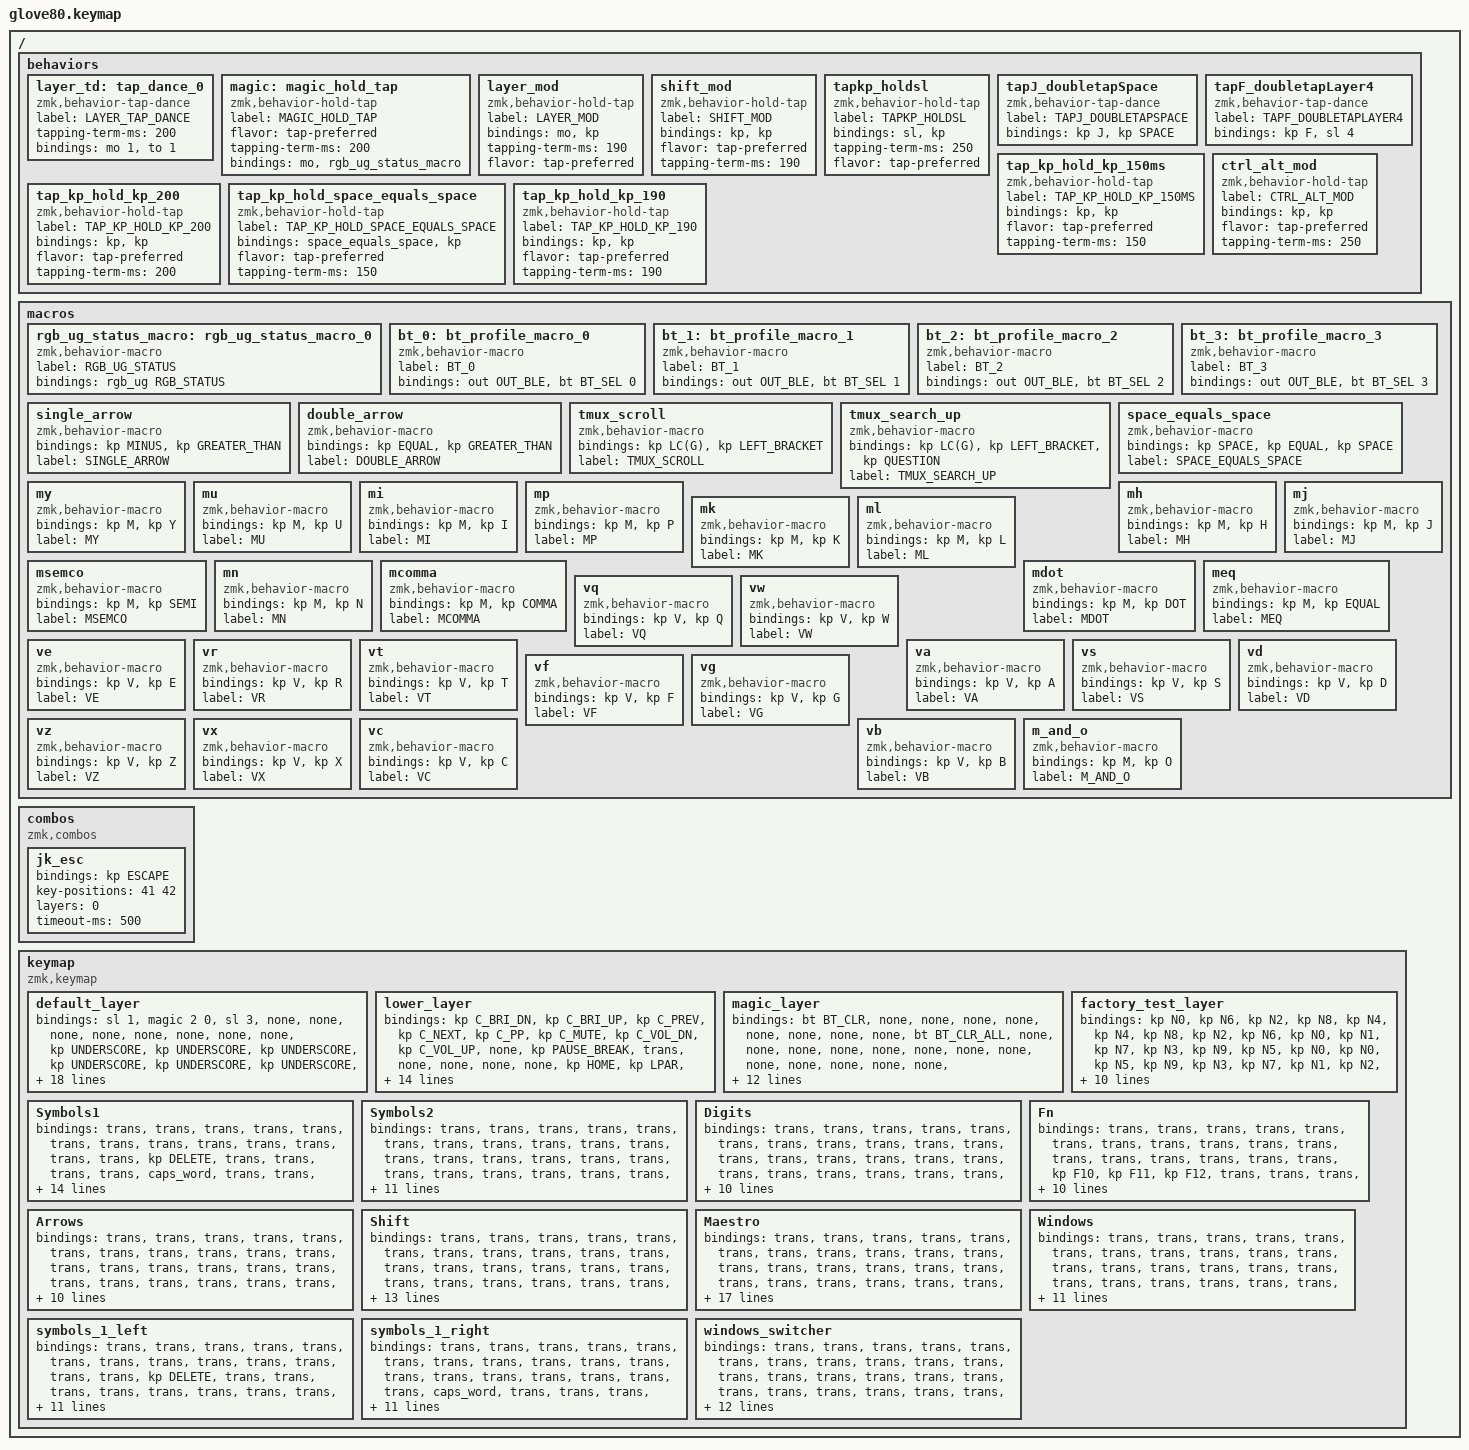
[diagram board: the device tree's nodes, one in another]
/*
 * Copyright (c) 2020 The ZMK Contributors
 *
 * SPDX-License-Identifier: MIT
 */

#include <behaviors.dtsi>
#include <dt-bindings/zmk/bt.h>
#include <dt-bindings/zmk/keys.h>
#include <dt-bindings/zmk/outputs.h>
#include <dt-bindings/zmk/rgb.h>

#define HYPER LC(LS(LG(LALT)))

// layers

#define DEFAULT 0
#define LOWER 1
#define MAGIC 2
#define FACTORY_TEST 3

/ {
    behaviors {
        // For the "layer" key, it'd nice to be able to use it as either a shift or a toggle.
        // Configure it as a tap dance, so the first tap (or hold) is a &mo and the second tap is a &to

        layer_td: tap_dance_0 {
            compatible = "zmk,behavior-tap-dance";
            label = "LAYER_TAP_DANCE";
            #binding-cells = <0>;
            tapping-term-ms = <200>;
            bindings = <&mo 1>, <&to 1>;
        };

        magic: magic_hold_tap {
            compatible = "zmk,behavior-hold-tap";
            label = "MAGIC_HOLD_TAP";
            #binding-cells = <2>;
            flavor = "tap-preferred";
            tapping-term-ms = <200>;
            bindings = <&mo>, <&rgb_ug_status_macro>;
        };

        layer_mod: layer_mod {
            compatible = "zmk,behavior-hold-tap";
            label = "LAYER_MOD";
            bindings = <&mo>, <&kp>;

            #binding-cells = <2>;
            tapping-term-ms = <190>;
            flavor = "tap-preferred";
        };

        shift_mod: shift_mod {
            compatible = "zmk,behavior-hold-tap";
            label = "SHIFT_MOD";
            bindings = <&kp>, <&kp>;

            #binding-cells = <2>;
            flavor = "tap-preferred";
            tapping-term-ms = <190>;
        };

        tapkp_holdsl: tapkp_holdsl {
            compatible = "zmk,behavior-hold-tap";
            label = "TAPKP_HOLDSL";
            bindings = <&sl>, <&kp>;

            #binding-cells = <2>;
            tapping-term-ms = <250>;
            flavor = "tap-preferred";
        };

        tapJ_doubletapSpace: tapJ_doubletapSpace {
            compatible = "zmk,behavior-tap-dance";
            label = "TAPJ_DOUBLETAPSPACE";
            #binding-cells = <0>;
            bindings = <&kp J>, <&kp SPACE>;
        };

        tapF_doubletapLayer4: tapF_doubletapLayer4 {
            compatible = "zmk,behavior-tap-dance";
            label = "TAPF_DOUBLETAPLAYER4";
            #binding-cells = <0>;
            bindings = <&kp F>, <&sl 4>;
        };

        tap_kp_hold_kp_150ms: tap_kp_hold_kp_150ms {
            compatible = "zmk,behavior-hold-tap";
            label = "TAP_KP_HOLD_KP_150MS";
            bindings = <&kp>, <&kp>;

            #binding-cells = <2>;
            flavor = "tap-preferred";
            tapping-term-ms = <150>;
        };

        ctrl_alt_mod: ctrl_alt_mod {
            compatible = "zmk,behavior-hold-tap";
            label = "CTRL_ALT_MOD";
            bindings = <&kp>, <&kp>;

            #binding-cells = <2>;
            flavor = "tap-preferred";
            tapping-term-ms = <250>;
        };

        tap_kp_hold_kp_200: tap_kp_hold_kp_200 {
            compatible = "zmk,behavior-hold-tap";
            label = "TAP_KP_HOLD_KP_200";
            bindings = <&kp>, <&kp>;

            #binding-cells = <2>;
            flavor = "tap-preferred";
            tapping-term-ms = <200>;
        };

        tap_kp_hold_space_equals_space: tap_kp_hold_space_equals_space {
            compatible = "zmk,behavior-hold-tap";
            label = "TAP_KP_HOLD_SPACE_EQUALS_SPACE";
            bindings = <&space_equals_space>, <&kp>;

            #binding-cells = <2>;
            flavor = "tap-preferred";
            tapping-term-ms = <150>;
        };

        tap_kp_hold_kp_190: tap_kp_hold_kp_190 {
            compatible = "zmk,behavior-hold-tap";
            label = "TAP_KP_HOLD_KP_190";
            bindings = <&kp>, <&kp>;

            #binding-cells = <2>;
            flavor = "tap-preferred";
            tapping-term-ms = <190>;
        };
    };

    macros {
        rgb_ug_status_macro: rgb_ug_status_macro_0 {
            label = "RGB_UG_STATUS";
            compatible = "zmk,behavior-macro";
            #binding-cells = <0>;
            bindings = <&rgb_ug RGB_STATUS>;
        };

        bt_0: bt_profile_macro_0 {
            label = "BT_0";
            compatible = "zmk,behavior-macro";
            #binding-cells = <0>;
            bindings = <&out OUT_BLE &bt BT_SEL 0>;
        };

        bt_1: bt_profile_macro_1 {
            label = "BT_1";
            compatible = "zmk,behavior-macro";
            #binding-cells = <0>;
            bindings = <&out OUT_BLE &bt BT_SEL 1>;
        };

        bt_2: bt_profile_macro_2 {
            label = "BT_2";
            compatible = "zmk,behavior-macro";
            #binding-cells = <0>;
            bindings = <&out OUT_BLE &bt BT_SEL 2>;
        };

        bt_3: bt_profile_macro_3 {
            label = "BT_3";
            compatible = "zmk,behavior-macro";
            #binding-cells = <0>;
            bindings = <&out OUT_BLE &bt BT_SEL 3>;
        };

        single_arrow: single_arrow {
            compatible = "zmk,behavior-macro";
            #binding-cells = <0>;
            bindings = <&kp MINUS &kp GREATER_THAN>;
            label = "SINGLE_ARROW";
        };

        double_arrow: double_arrow {
            compatible = "zmk,behavior-macro";
            #binding-cells = <0>;
            bindings = <&kp EQUAL &kp GREATER_THAN>;
            label = "DOUBLE_ARROW";
        };

        tmux_scroll: tmux_scroll {
            compatible = "zmk,behavior-macro";
            #binding-cells = <0>;
            bindings = <&kp LC(G) &kp LEFT_BRACKET>;
            label = "TMUX_SCROLL";
        };

        tmux_search_up: tmux_search_up {
            compatible = "zmk,behavior-macro";
            #binding-cells = <0>;
            bindings = <&kp LC(G) &kp LEFT_BRACKET &kp QUESTION>;
            label = "TMUX_SEARCH_UP";
        };

        space_equals_space: space_equals_space {
            compatible = "zmk,behavior-macro";
            #binding-cells = <0>;
            bindings = <&kp SPACE &kp EQUAL &kp SPACE>;
            label = "SPACE_EQUALS_SPACE";
        };

        my: my {
            compatible = "zmk,behavior-macro";
            #binding-cells = <0>;
            bindings = <&kp M &kp Y>;
            label = "MY";
        };

        mu: mu {
            compatible = "zmk,behavior-macro";
            #binding-cells = <0>;
            bindings = <&kp M &kp U>;
            label = "MU";
        };

        mi: mi {
            compatible = "zmk,behavior-macro";
            #binding-cells = <0>;
            bindings = <&kp M &kp I>;
            label = "MI";
        };

        mp: mp {
            compatible = "zmk,behavior-macro";
            #binding-cells = <0>;
            bindings = <&kp M &kp P>;
            label = "MP";
        };

        mh: mh {
            compatible = "zmk,behavior-macro";
            #binding-cells = <0>;
            bindings = <&kp M &kp H>;
            label = "MH";
        };

        mj: mj {
            compatible = "zmk,behavior-macro";
            #binding-cells = <0>;
            bindings = <&kp M &kp J>;
            label = "MJ";
        };

        mk: mk {
            compatible = "zmk,behavior-macro";
            #binding-cells = <0>;
            bindings = <&kp M &kp K>;
            label = "MK";
        };

        ml: ml {
            compatible = "zmk,behavior-macro";
            #binding-cells = <0>;
            bindings = <&kp M &kp L>;
            label = "ML";
        };

        msemco: msemco {
            compatible = "zmk,behavior-macro";
            #binding-cells = <0>;
            bindings = <&kp M &kp SEMI>;
            label = "MSEMCO";
        };

        mn: mn {
            compatible = "zmk,behavior-macro";
            #binding-cells = <0>;
            bindings = <&kp M &kp N>;
            label = "MN";
        };

        mcomma: mcomma {
            compatible = "zmk,behavior-macro";
            #binding-cells = <0>;
            bindings = <&kp M &kp COMMA>;
            label = "MCOMMA";
        };

        mdot: mdot {
            compatible = "zmk,behavior-macro";
            #binding-cells = <0>;
            bindings = <&kp M &kp DOT>;
            label = "MDOT";
        };

        meq: meq {
            compatible = "zmk,behavior-macro";
            #binding-cells = <0>;
            bindings = <&kp M &kp EQUAL>;
            label = "MEQ";
        };

        vq: vq {
            compatible = "zmk,behavior-macro";
            #binding-cells = <0>;
            bindings = <&kp V &kp Q>;
            label = "VQ";
        };

        vw: vw {
            compatible = "zmk,behavior-macro";
            #binding-cells = <0>;
            bindings = <&kp V &kp W>;
            label = "VW";
        };

        ve: ve {
            compatible = "zmk,behavior-macro";
            #binding-cells = <0>;
            bindings = <&kp V &kp E>;
            label = "VE";
        };

        vr: vr {
            compatible = "zmk,behavior-macro";
            #binding-cells = <0>;
            bindings = <&kp V &kp R>;
            label = "VR";
        };

        vt: vt {
            compatible = "zmk,behavior-macro";
            #binding-cells = <0>;
            bindings = <&kp V &kp T>;
            label = "VT";
        };

        va: va {
            compatible = "zmk,behavior-macro";
            #binding-cells = <0>;
            bindings = <&kp V &kp A>;
            label = "VA";
        };

        vs: vs {
            compatible = "zmk,behavior-macro";
            #binding-cells = <0>;
            bindings = <&kp V &kp S>;
            label = "VS";
        };

        vd: vd {
            compatible = "zmk,behavior-macro";
            #binding-cells = <0>;
            bindings = <&kp V &kp D>;
            label = "VD";
        };

        vf: vf {
            compatible = "zmk,behavior-macro";
            #binding-cells = <0>;
            bindings = <&kp V &kp F>;
            label = "VF";
        };

        vg: vg {
            compatible = "zmk,behavior-macro";
            #binding-cells = <0>;
            bindings = <&kp V &kp G>;
            label = "VG";
        };

        vz: vz {
            compatible = "zmk,behavior-macro";
            #binding-cells = <0>;
            bindings = <&kp V &kp Z>;
            label = "VZ";
        };

        vx: vx {
            compatible = "zmk,behavior-macro";
            #binding-cells = <0>;
            bindings = <&kp V &kp X>;
            label = "VX";
        };

        vc: vc {
            compatible = "zmk,behavior-macro";
            #binding-cells = <0>;
            bindings = <&kp V &kp C>;
            label = "VC";
        };

        vb: vb {
            compatible = "zmk,behavior-macro";
            #binding-cells = <0>;
            bindings = <&kp V &kp B>;
            label = "VB";
        };

        m_and_o: m_and_o {
            compatible = "zmk,behavior-macro";
            #binding-cells = <0>;
            bindings = <&kp M &kp O>;
            label = "M_AND_O";
        };
    };

    combos {
        compatible = "zmk,combos";

        jk_esc {
            bindings = <&kp ESCAPE>;
            key-positions = <41 42>;
            layers = <0>;
            timeout-ms = <500>;
        };
    };

    keymap {
        compatible = "zmk,keymap";

        default_layer {
            // ---------------------------------------------------------------------------------------------------------------------------------
            // |  F1   |  F2 |  F3 |  F4  |  F5  |                                                               |  F6   |  F7   |  F8  |   F9  |  F10 |
            // |  =    |  1  |  2  |  3   |  4   |  5   |                                                 |  6   |   7   |   8   |  9   |   0   |   -  |
            // |  TAB  |  Q  |  W  |  E   |  R   |  T   |                                                 |  Y   |   U   |   I   |  O   |   P   |   \  |
            // |  ESC  |  A  |  S  |  D   |  F   |  G   |                                                 |  H   |   J   |   K   |  L   |   ;   |   '  |
            // |   `   |  Z  |  X  |  C   |  V   |  B   | LSHFT | LCTRL | LOWER | | LGUI  | RCTRL | RSHFT |  N   |   M   |   ,   |  .   |   /   | PGUP |
            // | MAGIC | HOME| END | LEFT | RIGHT|      | BSPC  | DEL   | LALT  | | RALT  | RET   | SPACE |      |  UP   | DOWN  |  [   |   ]   | PGDN |

            bindings = <
&sl 1           &magic 2 0            &sl 3                 &none                  &none                                                                                                          &none                    &none                        &none                 &none                   &none
&none           &kp UNDERSCORE        &kp UNDERSCORE        &kp UNDERSCORE         &kp UNDERSCORE           &kp UNDERSCORE                                                        &kp UNDERSCORE  &kp UNDERSCORE           &kp UNDERSCORE               &kp UNDERSCORE        &kp UNDERSCORE          &none
&kp UNDERSCORE  &ctrl_alt_mod LGUI Q  &ctrl_alt_mod LALT W  &ctrl_alt_mod LCTRL E  &kp R                    &kp T                                                                 &kp Y           &kp U                    &ctrl_alt_mod LCTRL I        &ctrl_alt_mod LALT O  &ctrl_alt_mod LGUI P    &kp UNDERSCORE
&kp BACKSPACE   &layer_mod 8 A        &layer_mod 14 S       &layer_mod 6 D         &shift_mod LEFT_SHIFT F  &layer_mod 7 G                                                        &kp H           &shift_mod LEFT_SHIFT J  &tap_kp_hold_kp_200 K SPACE  &kp L                 &layer_mod 5 SEMICOLON  &kp ENTER
&tog 0          &kp Z                 &kp X                 &kp C                  &layer_mod 13 V          &kp B           &none  &none          &none  &none  &none      &none  &kp N           &layer_mod 12 M          &kp COMMA                    &kp DOT               &kp EQUAL               &none
&magic 2 0      &none                 &none                 &none                  &none                                    &none  &kp BACKSPACE  &none  &none  &kp ENTER  &none                  &none                    &none                        &none                 &none                   &none
            >;
        };

        lower_layer {
            bindings = <
&kp C_BRI_DN  &kp C_BRI_UP  &kp C_PREV  &kp C_NEXT  &kp C_PP                                                                         &kp C_MUTE  &kp C_VOL_DN  &kp C_VOL_UP   &none            &kp PAUSE_BREAK
&trans        &none         &none       &none       &none      &kp HOME                                                   &kp LPAR   &kp KP_NUM  &kp KP_EQUAL  &kp KP_DIVIDE  &kp KP_MULTIPLY  &kp PSCRN
&trans        &none         &none       &kp UP      &none      &kp END                                                    &kp RPAR   &kp KP_N7   &kp KP_N8     &kp KP_N9      &kp KP_MINUS     &kp SLCK
&trans        &none         &kp LEFT    &kp DOWN    &kp RIGHT  &kp PG_UP                                                  &kp PRCNT  &kp KP_N4   &kp KP_N5     &kp KP_N6      &kp KP_PLUS      &none
&trans        &kp K_CMENU   &none       &kp F11     &kp F12    &kp PG_DN  &trans  &trans  &to 0   &trans  &trans  &trans  &kp COMMA  &kp KP_N1   &kp KP_N2     &kp KP_N3      &kp KP_ENTER     &trans
&trans        &kp CAPS      &kp INS     &kp F11     &kp F12               &trans  &trans  &trans  &trans  &trans  &trans             &kp KP_N0   &kp KP_N0     &kp KP_DOT     &kp KP_ENTER     &trans
            >;
        };

        magic_layer {
            bindings = <
&bt BT_CLR   &none            &none            &none            &none                                                                                     &none  &none  &none  &none  &bt BT_CLR_ALL
&none        &none            &none            &none            &none            &none                                                             &none  &none  &none  &none  &none  &none
&none        &rgb_ug RGB_SPI  &rgb_ug RGB_SAI  &rgb_ug RGB_HUI  &rgb_ug RGB_BRI  &rgb_ug RGB_TOG                                                   &none  &none  &none  &none  &none  &none
&bootloader  &rgb_ug RGB_SPD  &rgb_ug RGB_SAD  &rgb_ug RGB_HUD  &rgb_ug RGB_BRD  &rgb_ug RGB_EFF                                                   &none  &none  &none  &none  &none  &bootloader
&sys_reset   &none            &none            &none            &none            &none            &bt_2  &bt_3  &none         &none  &none  &none  &none  &none  &none  &none  &none  &sys_reset
&none        &none            &none            &none            &none                             &bt_0  &bt_1  &out OUT_USB  &none  &none  &none         &none  &none  &none  &none  &to 3
            >;
        };

        factory_test_layer {
            bindings = <
&kp N0  &kp N6  &kp N2  &kp N8  &kp N4                                                                  &kp N4  &kp N8  &kp N2  &kp N6  &kp N0
&kp N1  &kp N7  &kp N3  &kp N9  &kp N5  &kp N0                                                  &kp N0  &kp N5  &kp N9  &kp N3  &kp N7  &kp N1
&kp N2  &kp N8  &kp N4  &kp N0  &kp N6  &kp N1                                                  &kp N1  &kp N6  &kp N0  &kp N4  &kp N8  &kp N2
&kp N3  &kp N9  &kp N5  &kp N1  &kp N7  &kp N2                                                  &kp N2  &kp N7  &kp N1  &kp N5  &kp N9  &kp N3
&kp N4  &kp N0  &kp N6  &kp N2  &kp N8  &kp N3  &kp N4  &kp N5  &kp N6  &kp N6  &kp N5  &kp N4  &kp N3  &kp N8  &kp N2  &kp N6  &kp N0  &kp N4
&kp N5  &kp N1  &kp N7  &kp N3  &kp N9          &kp N7  &kp N8  &kp N9  &kp N9  &kp N8  &kp N7          &kp N9  &kp N3  &kp N7  &kp N1  &kp N5
            >;
        };

        Symbols1 {
            bindings = <
&trans      &trans        &trans           &trans         &trans                                                                                               &trans         &trans        &trans        &trans         &trans
&trans      &trans        &trans           &kp DELETE     &trans         &trans                                                                 &trans         &trans         &caps_word    &trans        &trans         &trans
&trans      &trans        &tmux_search_up  &double_arrow  &single_arrow  &kp GRAVE                                                              &kp LS(TILDE)  &kp LS(UNDER)  &kp MINUS     &kp LS(DQT)   &kp SQT        &trans
&kp DELETE  &tmux_scroll  &kp LC(G)        &kp BSLH       &kp FSLH       &kp LBKT                                                               &kp RBKT       &kp LS(LPAR)   &kp LS(RPAR)  &kp LS(LBRC)  &kp LS(RBRC)   &caps_word
&trans      &trans        &trans           &kp LS(LC(C))  &kp LS(LC(V))  &trans     &trans  &trans      &trans  &trans  &trans      &caps_word  &kp TAB        &kp LS(AMPS)   &kp LS(STAR)  &kp LS(PIPE)  &kp LS(QMARK)  &trans
&trans      &trans        &trans           &trans         &trans                    &trans  &kp DELETE  &trans  &trans  &caps_word  &kp TAB                    &trans         &trans        &trans        &trans         &trans
            >;
        };

        Symbols2 {
            bindings = <
&trans  &trans        &trans      &trans         &trans                                                                               &trans  &trans  &trans  &trans  &trans
&trans  &trans        &trans      &trans         &trans        &trans                                                         &trans  &trans  &trans  &trans  &trans  &trans
&trans  &trans        &trans      &kp LS(LT)     &kp LS(GT)    &kp LS(CARET)                                                  &trans  &trans  &trans  &trans  &trans  &trans
&trans  &kp LS(EXCL)  &kp LS(AT)  &kp LS(POUND)  &kp LS(DLLR)  &kp LS(PRCNT)                                                  &trans  &trans  &trans  &trans  &trans  &trans
&trans  &trans        &trans      &trans         &trans        &trans         &trans  &trans  &trans  &trans  &trans  &trans  &trans  &trans  &trans  &trans  &trans  &trans
&trans  &trans        &trans      &trans         &trans                       &trans  &trans  &trans  &trans  &trans  &trans          &trans  &trans  &trans  &trans  &trans
            >;
        };

        Digits {
            bindings = <
&trans  &trans  &trans  &trans  &trans                                                                  &trans  &trans  &trans  &trans  &trans
&trans  &trans  &trans  &trans  &trans  &trans                                                  &trans  &trans  &trans  &trans  &trans  &trans
&trans  &trans  &trans  &trans  &trans  &trans                                                  &trans  &kp N7  &kp N8  &kp N9  &trans  &trans
&trans  &trans  &trans  &trans  &trans  &trans                                                  &kp N0  &kp N4  &kp N5  &kp N6  &trans  &trans
&trans  &trans  &trans  &trans  &trans  &trans  &trans  &trans  &trans  &trans  &trans  &trans  &trans  &kp N1  &kp N2  &kp N3  &trans  &trans
&trans  &trans  &trans  &trans  &trans          &trans  &trans  &trans  &trans  &trans  &trans          &trans  &trans  &trans  &trans  &trans
            >;
        };

        Fn {
            bindings = <
&trans  &trans  &trans  &trans  &trans                                                                  &trans   &trans   &trans   &trans  &trans
&trans  &trans  &trans  &trans  &trans  &trans                                                  &trans  &kp F10  &kp F11  &kp F12  &trans  &trans
&trans  &trans  &trans  &trans  &trans  &trans                                                  &trans  &kp F7   &kp F8   &kp F9   &trans  &trans
&trans  &trans  &trans  &trans  &trans  &trans                                                  &trans  &kp F4   &kp F5   &kp F6   &trans  &trans
&trans  &trans  &trans  &trans  &trans  &trans  &trans  &trans  &trans  &trans  &trans  &trans  &trans  &kp F1   &kp F2   &kp F3   &trans  &trans
&trans  &trans  &trans  &trans  &trans          &trans  &trans  &trans  &trans  &trans  &trans          &trans   &trans   &trans   &trans  &trans
            >;
        };

        Arrows {
            bindings = <
&trans  &trans  &trans  &trans  &trans                                                                    &trans         &trans       &trans     &trans  &trans
&trans  &trans  &trans  &trans  &trans  &trans                                                  &trans    &trans         &trans       &trans     &trans  &trans
&trans  &trans  &trans  &trans  &trans  &trans                                                  &kp HOME  &kp PAGE_DOWN  &kp PAGE_UP  &kp END    &trans  &trans
&trans  &trans  &trans  &trans  &trans  &trans                                                  &kp LEFT  &kp DOWN       &kp UP       &kp RIGHT  &trans  &trans
&trans  &trans  &trans  &trans  &trans  &trans  &trans  &trans  &trans  &trans  &trans  &trans  &trans    &trans         &trans       &trans     &trans  &trans
&trans  &trans  &trans  &trans  &trans          &trans  &trans  &trans  &trans  &trans  &trans            &trans         &trans       &trans     &trans  &trans
            >;
        };

        Shift {
            bindings = <
&trans  &trans     &trans     &trans     &trans                                                                           &trans     &trans      &trans      &trans         &trans
&trans  &trans     &trans     &trans     &trans     &trans                                                     &trans     &trans     &trans      &trans      &trans         &trans
&trans  &kp LS(Q)  &kp LS(W)  &kp LS(E)  &kp LS(R)  &kp LS(T)                                                  &kp LS(Y)  &kp LS(U)  &kp LS(I)   &kp LS(O)   &kp LS(P)      &trans
&trans  &kp LS(A)  &kp LS(S)  &kp LS(D)  &kp LS(F)  &kp LS(G)                                                  &kp LS(H)  &kp LS(J)  &kp LS(K)   &kp LS(L)   &kp LS(COLON)  &kp LS(ENTER)
&trans  &kp LS(Z)  &kp LS(X)  &kp LS(C)  &kp LS(V)  &kp LS(B)  &trans  &trans  &trans  &trans  &trans  &trans  &kp LS(N)  &kp LS(M)  &kp LS(LT)  &kp LS(GT)  &kp LS(PLUS)   &trans
&trans  &trans     &trans     &trans     &trans                &trans  &trans  &trans  &trans  &trans  &trans             &trans     &trans      &trans      &trans         &trans
            >;
        };

        Maestro {
            bindings = <
&trans  &trans  &trans  &trans  &trans                                                                                        &trans                        &trans                        &trans                        &trans  &trans
&trans  &trans  &trans  &trans  &trans  &trans                                                  &trans                        &trans                        &trans                        &trans                        &trans  &trans
&trans  &trans  &trans  &trans  &trans  &trans                                                  &trans                        &kp LA(LG(LS(LC(NUMBER_7))))  &kp LA(LG(LS(LC(NUMBER_8))))  &kp LA(LG(LS(LC(NUMBER_9))))  &trans  &trans
&trans  &trans  &trans  &trans  &trans  &trans                                                  &kp LA(LG(LS(LC(NUMBER_0))))  &kp LA(LG(LS(LC(NUMBER_4))))  &kp LA(LG(LS(LC(NUMBER_5))))  &kp LA(LG(LS(LC(NUMBER_6))))  &trans  &trans
&trans  &trans  &trans  &trans  &trans  &trans  &trans  &trans  &trans  &trans  &trans  &trans  &trans                        &kp LA(LG(LS(LC(NUMBER_1))))  &kp LA(LG(LS(LC(NUMBER_2))))  &kp LA(LG(LS(LC(NUMBER_3))))  &trans  &trans
&trans  &trans  &trans  &trans  &trans          &trans  &trans  &trans  &trans  &trans  &trans                                &trans                        &trans                        &trans                        &trans  &trans
            >;
        };

        Windows {
            bindings = <
&trans  &trans  &trans  &trans  &trans                                                                      &trans      &trans      &trans      &trans  &trans
&trans  &trans  &trans  &trans  &trans  &trans                                                  &trans      &trans      &trans      &trans      &trans  &trans
&trans  &trans  &trans  &trans  &trans  &trans                                                  &trans      &kp LG(N7)  &kp LG(N8)  &kp LG(N9)  &trans  &trans
&trans  &trans  &trans  &trans  &trans  &trans                                                  &kp LG(N0)  &kp LG(N4)  &kp K       &kp LG(N6)  &trans  &trans
&trans  &trans  &trans  &trans  &trans  &trans  &trans  &trans  &trans  &trans  &trans  &trans  &trans      &kp LG(N1)  &kp LG(N2)  &kp LG(N3)  &trans  &trans
&trans  &trans  &trans  &trans  &trans          &trans  &trans  &trans  &trans  &trans  &trans              &trans      &trans      &trans      &trans  &trans
            >;
        };

        symbols_1_left {
            bindings = <
&trans      &trans        &trans           &trans         &trans                                                                                        &trans  &trans   &trans    &trans   &trans
&trans      &trans        &trans           &kp DELETE     &trans         &trans                                                                 &trans  &trans  &trans   &trans    &trans   &trans
&trans      &trans        &tmux_search_up  &double_arrow  &single_arrow  &kp GRAVE                                                              &my     &mu     &mi      &m_and_o  &mp      &trans
&kp DELETE  &tmux_scroll  &kp LC(G)        &kp BSLH       &kp FSLH       &kp LBKT                                                               &mh     &mj     &mk      &ml       &msemco  &trans
&trans      &trans        &trans           &kp LS(LC(C))  &kp LS(LC(V))  &trans     &trans  &trans      &trans  &trans  &trans      &caps_word  &mn     &trans  &mcomma  &mdot     &meq     &trans
&trans      &trans        &trans           &trans         &trans                    &trans  &kp DELETE  &trans  &trans  &caps_word  &kp TAB             &trans  &trans   &trans    &trans   &trans
            >;
        };

        symbols_1_right {
            bindings = <
&trans  &trans  &trans  &trans  &trans                                                                                 &trans         &trans        &trans        &trans         &trans
&trans  &trans  &trans  &trans  &trans  &trans                                                          &trans         &trans         &caps_word    &trans        &trans         &trans
&trans  &vq     &vw     &ve     &vr     &vt                                                             &kp LS(TILDE)  &kp LS(UNDER)  &kp MINUS     &kp LS(DQT)   &kp SQT        &trans
&trans  &va     &vs     &vd     &vf     &vg                                                             &kp RBKT       &kp LS(LPAR)   &kp LS(RPAR)  &kp LS(LBRC)  &kp LS(RBRC)   &caps_word
&trans  &vz     &vx     &vc     &trans  &vb     &trans  &trans  &trans  &trans  &trans      &caps_word  &kp TAB        &kp LS(AMPS)   &kp LS(STAR)  &kp LS(PIPE)  &kp LS(QMARK)  &trans
&trans  &trans  &trans  &trans  &trans          &trans  &trans  &trans  &trans  &caps_word  &kp TAB                    &trans         &trans        &trans        &trans         &trans
            >;
        };

        windows_switcher {
            bindings = <
&trans  &trans  &trans  &trans  &trans                                                                            &trans            &trans            &trans            &trans  &trans
&trans  &trans  &trans  &trans  &trans  &trans                                                  &trans            &trans            &trans            &trans            &trans  &trans
&trans  &trans  &trans  &trans  &trans  &trans                                                  &trans            &kp LG(N8)        &kp LG(N9)        &trans            &trans  &trans
&trans  &trans  &trans  &trans  &trans  &trans                                                  &kp LG(NUMBER_1)  &kp LG(N5)        &kp LG(NUMBER_6)  &kp LG(N7)        &trans  &trans
&trans  &trans  &trans  &trans  &trans  &trans  &trans  &trans  &trans  &trans  &trans  &trans  &trans            &kp LG(NUMBER_2)  &kp LG(NUMBER_3)  &kp LG(NUMBER_4)  &trans  &trans
&trans  &trans  &trans  &trans  &trans          &trans  &trans  &trans  &trans  &trans  &trans                    &trans            &trans            &trans            &trans  &trans
            >;
        };
    };
};
